# f28004x_i2c_regs register map
Vendor: Texas Instruments
Peripheral module from a debugger description file (folder C2000).
Address unit: 16 bits
Registers are 16-bit, read-write, no defined reset value unless marked. A register's access mark holds for its fields unless they carry their own. Offsets are as the file gives them; lines under a group give offsets from that group; [hi:lo] are bit positions; {n}, {i} and the like mark numbered series; 'fields as' and 'values as' point back to an identical list; <NAME> marks a mode.

## I2C_REGS — I2C Registers
0x00 I2COAR — I2C Own address
  [9:0] OAR
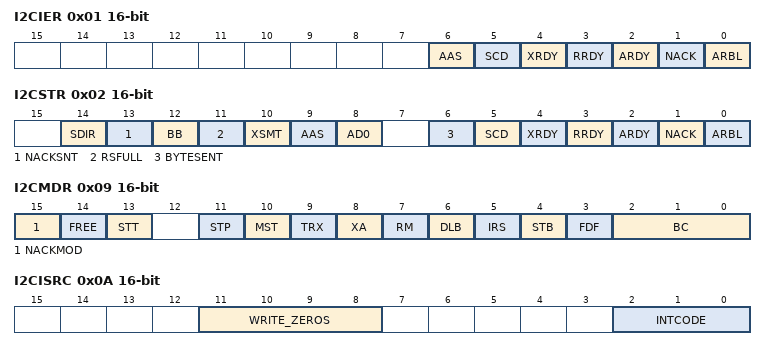
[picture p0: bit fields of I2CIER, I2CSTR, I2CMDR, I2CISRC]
0x01 I2CIER — I2C Interrupt Enable
  [6] AAS — Addressed as slave interrupt enable
  [5] SCD — Stop condition detected interrupt enable
  [4] XRDY — Transmit-data-ready interrupt enable
  [3] RRDY — Receive-data-ready interrupt enable
  [2] ARDY — Register-access-ready interrupt enable
  [1] NACK — No-acknowledgment interrupt enable
  [0] ARBL — Arbitration-lost interrupt enable
0x02 I2CSTR access not given — I2C Status
  [14] SDIR — Slave direction bit (access R/W1toClr)
  [13] NACKSNT — NACK sent bit. (access R/W1toClr)
  [12] BB ro — Bus busy bit.
  [11] RSFULL ro — Receive shift register full bit.
  [10] XSMT ro — Transmit shift register empty bit.
  [9] AAS ro — Addressed-as-slave bit
  [8] AD0 ro — Address 0 bits
  [6] BYTESENT — Byte transmit over indication (access R/W1toClr)
  [5] SCD — Stop condition detected bit. (access R/W1toClr)
  [4] XRDY ro — Transmit-data-ready interrupt flag bit.
  [3] RRDY — Receive-data-ready interrupt flag bit. (access R/W1toClr)
  [2] ARDY — Register-access-ready interrupt flag bit (access R/W1toClr)
  [1] NACK — No-acknowledgment interrupt flag bit. (access R/W1toClr)
  [0] ARBL — Arbitration-lost interrupt flag bit (access R/W1toClr)
0x03 I2CCLKL — I2C Clock low-time divider
  [15:0] I2CCLKL — Clock low-time divide-down value.
0x04 I2CCLKH — I2C Clock high-time divider
  [15:0] I2CCLKH — Clock high-time divide-down value.
0x05 I2CCNT — I2C Data count
  [15:0] I2CCNT — Data count value.
0x06 I2CDRR ro — I2C Data receive
  [7:0] DATA — Receive data
0x07 I2CSAR — I2C Slave address
  [9:0] SAR — Slave Address
0x08 I2CDXR — I2C Data Transmit
  [7:0] DATA — Transmit data
0x09 I2CMDR — I2C Mode
  [15] NACKMOD — NACK mode bit
  [14] FREE — Debug Action
  [13] STT — START condition bit
  [11] STP — STOP Condition
  [10] MST — Master Mode
  [9] TRX — Transmitter Mode
  [8] XA — Expanded Address Mode
  [7] RM — Repeat Mode
  [6] DLB — Digital Loopback Mode
  [5] IRS — I2C Module Reset
  [4] STB — START Byte Mode
  [3] FDF — Free Data Format
  [2:0] BC — Bit count bits.
0x0A I2CISRC access per field — I2C Interrupt Source
  [11:8] WRITE_ZEROS rw — Always write all 0s to this field
  [2:0] INTCODE ro — Interrupt code bits.
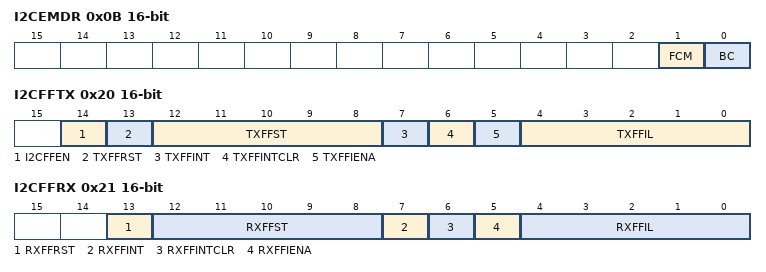
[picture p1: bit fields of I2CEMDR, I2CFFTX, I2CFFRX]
0x0B I2CEMDR — I2C Extended Mode
  [1] FCM — Forward Compatibility for Tx behav in Type1
  [0] BC — Backwards compatibility mode
0x0C I2CPSC — I2C Prescaler
  [7:0] IPSC — I2C Prescaler Divide Down
0x20 I2CFFTX access not given — I2C FIFO Transmit
  [14] I2CFFEN rw — Transmit FIFO Enable
  [13] TXFFRST rw — Transmit FIFO Reset
  [12:8] TXFFST ro — Transmit FIFO Status
  [7] TXFFINT ro — Transmit FIFO Interrupt Flag
  [6] TXFFINTCLR — Transmit FIFO Interrupt Flag Clear (access R=0/W=1)
  [5] TXFFIENA rw — Transmit FIFO Interrupt Enable
  [4:0] TXFFIL rw — Transmit FIFO Interrupt Level
0x21 I2CFFRX access not given — I2C FIFO Receive
  [13] RXFFRST rw — Receive FIFO Reset
  [12:8] RXFFST ro — Receive FIFO Status
  [7] RXFFINT ro — Receive FIFO Interrupt Flag
  [6] RXFFINTCLR — Receive FIFO Interrupt Flag Clear (access R=0/W=1)
  [5] RXFFIENA rw — Receive FIFO Interrupt Enable
  [4:0] RXFFIL rw — Receive FIFO Interrupt Level
